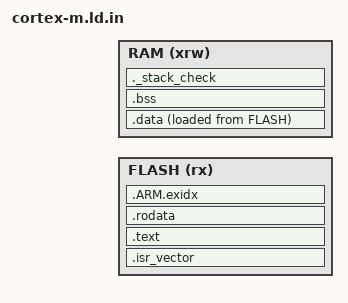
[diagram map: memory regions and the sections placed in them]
/*
 * Generic Cortex-M linker script, generated by CMake (@LINKER_SCRIPT_KIND@): do not edit.
 *
 * Used both for the bootloader and for the example applications: only the memory regions differ.
 */

ENTRY(Reset_Handler)

MEMORY
{
    FLASH (rx)  : ORIGIN = @LINKER_FLASH_ORIGIN@, LENGTH = @LINKER_FLASH_LENGTH@
    RAM   (xrw) : ORIGIN = @LINKER_RAM_ORIGIN@, LENGTH = @LINKER_RAM_LENGTH@
}

/* Initial stack pointer: end of the RAM. */
_estack = ORIGIN(RAM) + LENGTH(RAM);
/* Minimum stack size; checked to fit after the static data. */
_Min_Stack_Size = @LINKER_STACK_SIZE@;

SECTIONS
{
    .isr_vector :
    {
        . = ALIGN(4);
        KEEP(*(.isr_vector))
        . = ALIGN(4);
    } > FLASH

    .text :
    {
        . = ALIGN(4);
        *(.text)
        *(.text*)
        *(.glue_7)
        *(.glue_7t)
        *(.eh_frame)
        KEEP(*(.init))
        KEEP(*(.fini))
        . = ALIGN(4);
    } > FLASH

    .rodata :
    {
        . = ALIGN(4);
        *(.rodata)
        *(.rodata*)
        . = ALIGN(4);
    } > FLASH

    .ARM.exidx :
    {
        *(.ARM.exidx* .gnu.linkonce.armexidx.*)
    } > FLASH

    _sidata = LOADADDR(.data);

    .data :
    {
        . = ALIGN(4);
        _sdata = .;
        *(.data)
        *(.data*)
        *(.RamFunc)
        *(.RamFunc*)
        . = ALIGN(4);
        _edata = .;
    } > RAM AT > FLASH

    /* End of the image in flash (used for the size check and the .bin). */
    _eflash_image = LOADADDR(.data) + SIZEOF(.data);

    .bss (NOLOAD) :
    {
        . = ALIGN(4);
        _sbss = .;
        *(.bss)
        *(.bss*)
        *(COMMON)
        . = ALIGN(4);
        _ebss = .;
    } > RAM

    /* Check that the minimum stack fits in the RAM after the static data. */
    ._stack_check (NOLOAD) :
    {
        . = ALIGN(8);
        . = . + _Min_Stack_Size;
    } > RAM

    .ARM.attributes 0 : { *(.ARM.attributes) }
}
